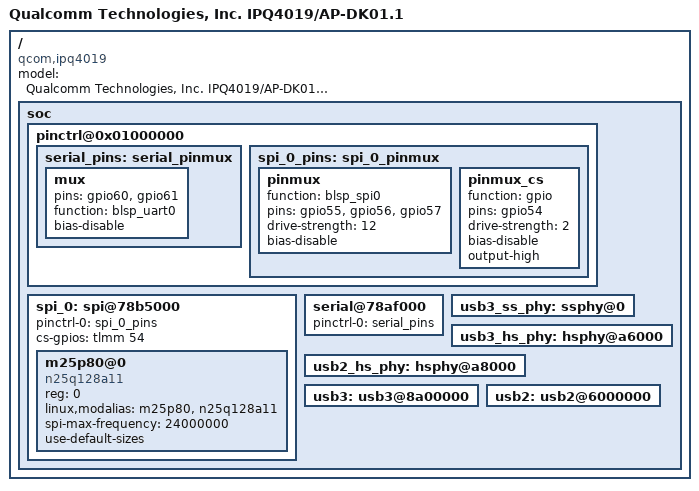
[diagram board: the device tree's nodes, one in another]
/* Copyright (c) 2015 - 2016, The Linux Foundation. All rights reserved.
 *
 * Permission to use, copy, modify, and/or distribute this software for any
 * purpose with or without fee is hereby granted, provided that the above
 * copyright notice and this permission notice appear in all copies.
 *
 * THE SOFTWARE IS PROVIDED "AS IS" AND THE AUTHOR DISCLAIMS ALL WARRANTIES
 * WITH REGARD TO THIS SOFTWARE INCLUDING ALL IMPLIED WARRANTIES OF
 * MERCHANTABILITY AND FITNESS. IN NO EVENT SHALL THE AUTHOR BE LIABLE FOR
 * ANY SPECIAL, DIRECT, INDIRECT, OR CONSEQUENTIAL DAMAGES OR ANY DAMAGES
 * WHATSOEVER RESULTING FROM LOSS OF USE, DATA OR PROFITS, WHETHER IN AN
 * ACTION OF CONTRACT, NEGLIGENCE OR OTHER TORTIOUS ACTION, ARISING OUT OF
 * OR IN CONNECTION WITH THE USE OR PERFORMANCE OF THIS SOFTWARE.
 *
 */

#include "qcom-ipq4019.dtsi"

/ {
	model = "Qualcomm Technologies, Inc. IPQ4019/AP-DK01.1";
	compatible = "qcom,ipq4019";

	soc {
		pinctrl@0x01000000 {
			serial_pins: serial_pinmux {
				mux {
					pins = "gpio60", "gpio61";
					function = "blsp_uart0";
					bias-disable;
				};
			};

			spi_0_pins: spi_0_pinmux {
				pinmux {
					function = "blsp_spi0";
					pins = "gpio55", "gpio56", "gpio57";
					drive-strength = <12>;
					bias-disable;
				};
				pinmux_cs {
					function = "gpio";
					pins = "gpio54";
					drive-strength = <2>;
					bias-disable;
					output-high;
				};
			};
		};

		spi_0: spi@78b5000 {
			pinctrl-0 = <&spi_0_pins>;
			pinctrl-names = "default";
			status = "ok";
			cs-gpios = <&tlmm 54 0>;

			m25p80@0 {
				#address-cells = <1>;
				#size-cells = <1>;
				compatible = "n25q128a11";
				reg = <0>;
				linux,modalias = "m25p80", "n25q128a11";
				spi-max-frequency = <24000000>;
				use-default-sizes;
			};

		};

		serial@78af000 {
			pinctrl-0 = <&serial_pins>;
			pinctrl-names = "default";
			status = "ok";
		};

		usb3_ss_phy: ssphy@0 {
			status = "ok";
		};

		usb3_hs_phy: hsphy@a6000 {
			status = "ok";
		};

		usb2_hs_phy: hsphy@a8000 {
			status = "ok";
		};

		usb3: usb3@8a00000 {
			status = "ok";
		};

		usb2: usb2@6000000 {
			status = "ok";
		};
	};
};
